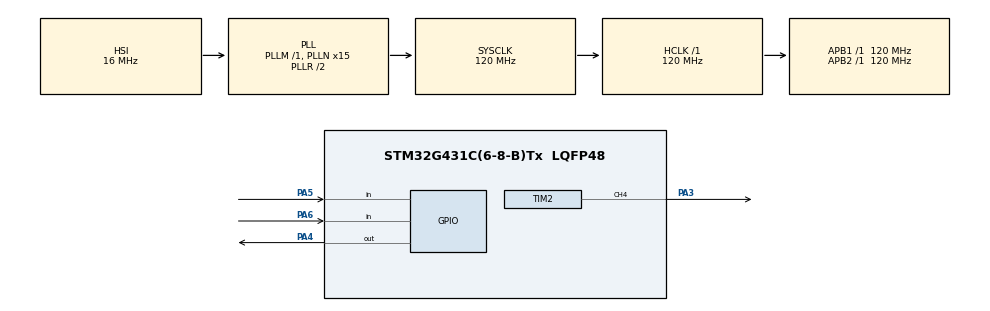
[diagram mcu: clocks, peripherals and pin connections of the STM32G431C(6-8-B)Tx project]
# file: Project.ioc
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Mcu.Family=STM32G4
Mcu.Name=STM32G431C(6-8-B)Tx
Mcu.Package=LQFP48
NVIC.PriorityGroup=NVIC_PRIORITYGROUP_4
PA13.Mode=Serial_Wire
PA13.Signal=SYS_JTMS-SWDIO
PA14.Mode=Serial_Wire
PA14.Signal=SYS_JTCK-SWCLK
PA3.Signal=S_TIM2_CH4
PA4.Signal=GPIO_Output
PA5.GPIO_PuPd=GPIO_PULLUP
PA5.Signal=GPIO_Input
PA6.GPIO_PuPd=GPIO_PULLUP
PA6.Signal=GPIO_Input
ProjectManager.HeapSize=0x200
ProjectManager.StackSize=0x400
ProjectManager.TargetToolchain=MDK-ARM V5.32
RCC.ADC12Freq_Value=120000000
RCC.AHBFreq_Value=120000000
RCC.APB1Freq_Value=120000000
RCC.APB1TimFreq_Value=120000000
RCC.APB2Freq_Value=120000000
RCC.APB2TimFreq_Value=120000000
RCC.CortexFreq_Value=120000000
RCC.EXTERNAL_CLOCK_VALUE=12288000
RCC.HCLKFreq_Value=120000000
RCC.HSE_VALUE=8000000
RCC.HSI48_VALUE=48000000
RCC.HSI_VALUE=16000000
RCC.LSE_VALUE=32768
RCC.PLLN=15
RCC.SYSCLKFreq_VALUE=120000000
RCC.SYSCLKSource=RCC_SYSCLKSOURCE_PLLCLK
RCC.USBFreq_Value=120000000
RCC.VCOOutputFreq_Value=240000000
SH.S_TIM2_CH4.0=TIM2_CH4,PWM Generation4 CH4
TIM2.Channel-PWM\ Generation4\ CH4=TIM_CHANNEL_4
TIM2.PeriodNoDither=1000 - 1
TIM2.Prescaler=120 - 1
VP_SYS_VS_DBSignals.Mode=DisableDeadBatterySignals
VP_TIM2_VS_ClockSourceINT.Mode=Internal
board=custom

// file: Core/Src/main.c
/* USER CODE BEGIN Header */
/**
  ******************************************************************************
  * @file           : main.c
  * @brief          : Main program body
  下载测试程序，K1控制LED，K2控制蜂鸣器
  ******************************************************************************
  * @attention
  *
  * Copyright (c) 2026 STMicroelectronics.
  * All rights reserved.
  *
  * This software is licensed under terms that can be found in the LICENSE file
  * in the root directory of this software component.
  * If no LICENSE file comes with this software, it is provided AS-IS.
  *
  ******************************************************************************
  */
/* USER CODE END Header */
#include "main.h"

TIM_HandleTypeDef htim2;

void SystemClock_Config(void);
static void MX_GPIO_Init(void);
static void MX_TIM2_Init(void);

/* USER CODE BEGIN 0 */
uint8_t led = 0, beep = 0;
/* USER CODE END 0 */

int main(void)
{

  /* MCU Configuration--------------------------------------------------------*/

  /* Reset of all peripherals, Initializes the Flash interface and the Systick. */
  HAL_Init();

  /* Configure the system clock */
  SystemClock_Config();

  /* Initialize all configured peripherals */
  MX_GPIO_Init();
  MX_TIM2_Init();
  /* USER CODE BEGIN 2 */
	HAL_TIM_PWM_Start(&htim2, TIM_CHANNEL_4);
  /* USER CODE END 2 */

  /* Infinite loop */
  /* USER CODE BEGIN WHILE */
  while (1)
  {
	  led = !HAL_GPIO_ReadPin(GPIOA, GPIO_PIN_5);
	  beep = !HAL_GPIO_ReadPin(GPIOA, GPIO_PIN_6);

	  HAL_GPIO_WritePin(GPIOA, GPIO_PIN_4, (GPIO_PinState)led);
	  if (beep) {
		__HAL_TIM_SET_COMPARE(&htim2, TIM_CHANNEL_4, 500);
	  }
	  else {
		__HAL_TIM_SET_COMPARE(&htim2, TIM_CHANNEL_4, 0);
	  }
    /* USER CODE END WHILE */

  }
}

void SystemClock_Config(void)
{
  RCC_OscInitTypeDef RCC_OscInitStruct = {0};
  RCC_ClkInitTypeDef RCC_ClkInitStruct = {0};

  /** Configure the main internal regulator output voltage
  */
  HAL_PWREx_ControlVoltageScaling(PWR_REGULATOR_VOLTAGE_SCALE1);

  /** Initializes the RCC Oscillators according to the specified parameters
  * in the RCC_OscInitTypeDef structure.
  */
  RCC_OscInitStruct.OscillatorType = RCC_OSCILLATORTYPE_HSI;
  RCC_OscInitStruct.HSIState = RCC_HSI_ON;
  RCC_OscInitStruct.HSICalibrationValue = RCC_HSICALIBRATION_DEFAULT;
  RCC_OscInitStruct.PLL.PLLState = RCC_PLL_ON;
  RCC_OscInitStruct.PLL.PLLSource = RCC_PLLSOURCE_HSI;
  RCC_OscInitStruct.PLL.PLLM = RCC_PLLM_DIV1;
  RCC_OscInitStruct.PLL.PLLN = 15;
  RCC_OscInitStruct.PLL.PLLP = RCC_PLLP_DIV2;
  RCC_OscInitStruct.PLL.PLLQ = RCC_PLLQ_DIV2;
  RCC_OscInitStruct.PLL.PLLR = RCC_PLLR_DIV2;
  if (HAL_RCC_OscConfig(&RCC_OscInitStruct) != HAL_OK)
  {
    Error_Handler();
  }

  /** Initializes the CPU, AHB and APB buses clocks
  */
  RCC_ClkInitStruct.ClockType = RCC_CLOCKTYPE_HCLK|RCC_CLOCKTYPE_SYSCLK
                              |RCC_CLOCKTYPE_PCLK1|RCC_CLOCKTYPE_PCLK2;
  RCC_ClkInitStruct.SYSCLKSource = RCC_SYSCLKSOURCE_PLLCLK;
  RCC_ClkInitStruct.AHBCLKDivider = RCC_SYSCLK_DIV1;
  RCC_ClkInitStruct.APB1CLKDivider = RCC_HCLK_DIV1;
  RCC_ClkInitStruct.APB2CLKDivider = RCC_HCLK_DIV1;

  if (HAL_RCC_ClockConfig(&RCC_ClkInitStruct, FLASH_LATENCY_3) != HAL_OK)
  {
    Error_Handler();
  }
}

static void MX_TIM2_Init(void)
{

  TIM_ClockConfigTypeDef sClockSourceConfig = {0};
  TIM_MasterConfigTypeDef sMasterConfig = {0};
  TIM_OC_InitTypeDef sConfigOC = {0};

  htim2.Instance = TIM2;
  htim2.Init.Prescaler = 120 - 1;
  htim2.Init.CounterMode = TIM_COUNTERMODE_UP;
  htim2.Init.Period = 999;
  htim2.Init.ClockDivision = TIM_CLOCKDIVISION_DIV1;
  htim2.Init.AutoReloadPreload = TIM_AUTORELOAD_PRELOAD_DISABLE;
  if (HAL_TIM_Base_Init(&htim2) != HAL_OK)
  {
    Error_Handler();
  }
  sClockSourceConfig.ClockSource = TIM_CLOCKSOURCE_INTERNAL;
  if (HAL_TIM_ConfigClockSource(&htim2, &sClockSourceConfig) != HAL_OK)
  {
    Error_Handler();
  }
  if (HAL_TIM_PWM_Init(&htim2) != HAL_OK)
  {
    Error_Handler();
  }
  sMasterConfig.MasterOutputTrigger = TIM_TRGO_RESET;
  sMasterConfig.MasterSlaveMode = TIM_MASTERSLAVEMODE_DISABLE;
  if (HAL_TIMEx_MasterConfigSynchronization(&htim2, &sMasterConfig) != HAL_OK)
  {
    Error_Handler();
  }
  sConfigOC.OCMode = TIM_OCMODE_PWM1;
  sConfigOC.Pulse = 0;
  sConfigOC.OCPolarity = TIM_OCPOLARITY_HIGH;
  sConfigOC.OCFastMode = TIM_OCFAST_DISABLE;
  if (HAL_TIM_PWM_ConfigChannel(&htim2, &sConfigOC, TIM_CHANNEL_4) != HAL_OK)
  {
    Error_Handler();
  }
  HAL_TIM_MspPostInit(&htim2);

}

static void MX_GPIO_Init(void)
{
  GPIO_InitTypeDef GPIO_InitStruct = {0};

  /* GPIO Ports Clock Enable */
  __HAL_RCC_GPIOA_CLK_ENABLE();

  /*Configure GPIO pin Output Level */
  HAL_GPIO_WritePin(GPIOA, GPIO_PIN_4, GPIO_PIN_RESET);

  /*Configure GPIO pin : PA4 */
  GPIO_InitStruct.Pin = GPIO_PIN_4;
  GPIO_InitStruct.Mode = GPIO_MODE_OUTPUT_PP;
  GPIO_InitStruct.Pull = GPIO_NOPULL;
  GPIO_InitStruct.Speed = GPIO_SPEED_FREQ_LOW;
  HAL_GPIO_Init(GPIOA, &GPIO_InitStruct);

  /*Configure GPIO pins : PA5 PA6 */
  GPIO_InitStruct.Pin = GPIO_PIN_5|GPIO_PIN_6;
  GPIO_InitStruct.Mode = GPIO_MODE_INPUT;
  GPIO_InitStruct.Pull = GPIO_PULLUP;
  HAL_GPIO_Init(GPIOA, &GPIO_InitStruct);

}

void Error_Handler(void)
{
  __disable_irq();
  while (1)
  {
  }
}
